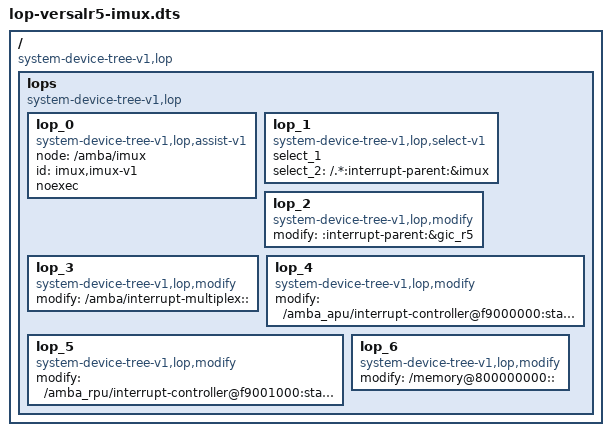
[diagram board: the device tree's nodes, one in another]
/*
 * Copyright (c) 2019,2020 Xilinx Inc. All rights reserved.
 *
 * Author:
 *       Bruce Ashfield <bruce.ashfield@xilinx.com>
 *
 * SPDX-License-Identifier: BSD-3-Clause
 */

/dts-v1/;

/ {
        compatible = "system-device-tree-v1,lop";
        lops {
                compatible = "system-device-tree-v1,lop";
                lop_0 {
                        compatible = "system-device-tree-v1,lop,assist-v1";
                        node = "/amba/imux";
                        id = "imux,imux-v1";
                        noexec;
                };
                lop_1 {
                      compatible = "system-device-tree-v1,lop,select-v1";
                      // clear any old selections
                      select_1;
                      select_2 = "/.*:interrupt-parent:&imux";
                };
                lop_2 {
                      compatible = "system-device-tree-v1,lop,modify";
                      // this will use the selected nodes above, to add a property
                      modify = ":interrupt-parent:&gic_r5";
                };
                lop_3 {
                        compatible = "system-device-tree-v1,lop,modify";
                        // delete the interrupt-multiplex
                        modify = "/amba/interrupt-multiplex::";
                };
                lop_4 {
                        compatible = "system-device-tree-v1,lop,modify";
                        // disable A72 interrupt controller
                        modify = "/amba_apu/interrupt-controller@f9000000:status:disabled";
                };
                lop_5 {
                        compatible = "system-device-tree-v1,lop,modify";
                        // enable R5 interrupt controller
                        modify = "/amba_rpu/interrupt-controller@f9001000:status:okay";
                };
                lop_6 {
                      compatible = "system-device-tree-v1,lop,modify";
                      // delete memory node
                      modify = "/memory@800000000::";
                };
        };
};
